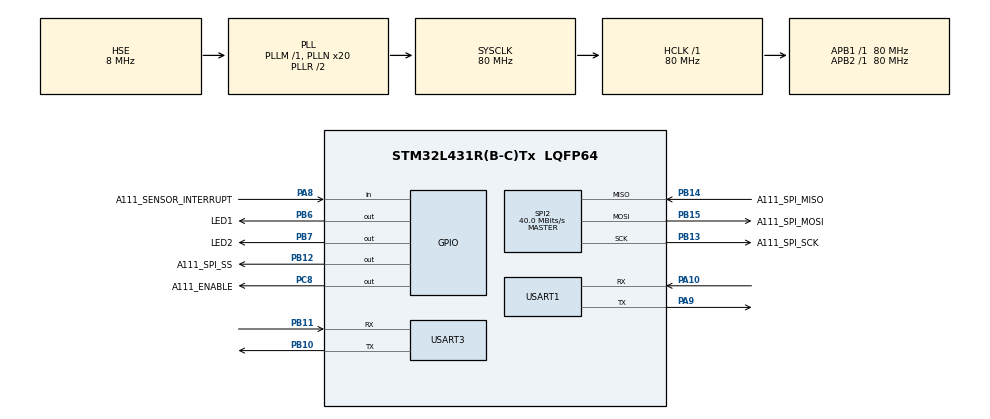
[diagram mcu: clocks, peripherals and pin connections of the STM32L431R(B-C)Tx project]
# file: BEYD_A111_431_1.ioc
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Mcu.Family=STM32L4
Mcu.Name=STM32L431R(B-C)Tx
Mcu.Package=LQFP64
NVIC.PriorityGroup=NVIC_PRIORITYGROUP_4
PA10.Mode=Asynchronous
PA10.Signal=USART1_RX
PA2.Signal=USART2_TX
PA3.Signal=USART2_RX
PA8.GPIO_Label=A111_SENSOR_INTERRUPT
PA8.Signal=GPIO_Input
PA9.Mode=Asynchronous
PA9.Signal=USART1_TX
PB10.Mode=Asynchronous
PB10.Signal=USART3_TX
PB11.Mode=Asynchronous
PB11.Signal=USART3_RX
PB12.GPIO_Label=A111_SPI_SS
PB12.Signal=GPIO_Output
PB13.GPIO_Label=A111_SPI_SCK
PB13.GPIO_Mode=GPIO_MODE_AF_PP
PB13.GPIO_PuPd=GPIO_NOPULL
PB13.GPIO_Speed=GPIO_SPEED_FREQ_VERY_HIGH
PB13.Mode=Full_Duplex_Master
PB13.Signal=SPI2_SCK
PB14.GPIO_Label=A111_SPI_MISO
PB14.GPIO_Mode=GPIO_MODE_AF_PP
PB14.GPIO_PuPd=GPIO_NOPULL
PB14.GPIO_Speed=GPIO_SPEED_FREQ_VERY_HIGH
PB14.Mode=Full_Duplex_Master
PB14.Signal=SPI2_MISO
PB15.GPIO_Label=A111_SPI_MOSI
PB15.GPIO_Mode=GPIO_MODE_AF_PP
PB15.GPIO_PuPd=GPIO_NOPULL
PB15.GPIO_Speed=GPIO_SPEED_FREQ_VERY_HIGH
PB15.Mode=Full_Duplex_Master
PB15.Signal=SPI2_MOSI
PB6.GPIO_Label=LED1
PB6.Signal=GPIO_Output
PB7.GPIO_Label=LED2
PB7.Signal=GPIO_Output
PC8.GPIO_Label=A111_ENABLE
PC8.Signal=GPIO_Output
PH0-OSC_IN\ (PH0).Mode=HSE-External-Oscillator
PH0-OSC_IN\ (PH0).Signal=RCC_OSC_IN
PH1-OSC_OUT\ (PH1).Mode=HSE-External-Oscillator
PH1-OSC_OUT\ (PH1).Signal=RCC_OSC_OUT
ProjectManager.HeapSize=0x200
ProjectManager.StackSize=0x400
ProjectManager.TargetToolchain=TrueSTUDIO
RCC.ADCFreq_Value=32000000
RCC.AHBFreq_Value=80000000
RCC.APB1Freq_Value=80000000
RCC.APB1TimFreq_Value=80000000
RCC.APB2Freq_Value=80000000
RCC.APB2TimFreq_Value=80000000
RCC.CortexFreq_Value=80000000
RCC.HCLKFreq_Value=80000000
RCC.HSE_VALUE=8000000
RCC.HSI48_VALUE=48000000
RCC.HSI_VALUE=16000000
RCC.LSE_VALUE=32768
RCC.MSI_VALUE=4000000
RCC.PLLN=20
RCC.PLLSourceVirtual=RCC_PLLSOURCE_HSE
RCC.SYSCLKFreq_VALUE=80000000
RCC.SYSCLKSource=RCC_SYSCLKSOURCE_PLLCLK
RCC.VCOOutputFreq_Value=160000000
SPI2.CalculateBaudRate=40.0 MBits/s
SPI2.Direction=SPI_DIRECTION_2LINES
SPI2.Mode=SPI_MODE_MASTER
SPI2.VirtualType=VM_MASTER
USART1.VirtualMode-Asynchronous=VM_ASYNC
USART3.VirtualMode-Asynchronous=VM_ASYNC
board=custom

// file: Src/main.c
/* USER CODE BEGIN Header */
/**
  ******************************************************************************
  * @file           : main.c
  * @brief          : Main program body
  ******************************************************************************
  ** This notice applies to any and all portions of this file
  * that are not between comment pairs USER CODE BEGIN and
  * USER CODE END. Other portions of this file, whether
  * inserted by the user or by software development tools
  * are owned by their respective copyright owners.
  *
  * COPYRIGHT(c) 2019 STMicroelectronics
  *
  * Redistribution and use in source and binary forms, with or without modification,
  * are permitted provided that the following conditions are met:
  *   1. Redistributions of source code must retain the above copyright notice,
  *      this list of conditions and the following disclaimer.
  *   2. Redistributions in binary form must reproduce the above copyright notice,
  *      this list of conditions and the following disclaimer in the documentation
  *      and/or other materials provided with the distribution.
  *   3. Neither the name of STMicroelectronics nor the names of its contributors
  *      may be used to endorse or promote products derived from this software
  *      without specific prior written permission.
  *
  * THIS SOFTWARE IS PROVIDED BY THE COPYRIGHT HOLDERS AND CONTRIBUTORS "AS IS"
  * AND ANY EXPRESS OR IMPLIED WARRANTIES, INCLUDING, BUT NOT LIMITED TO, THE
  * IMPLIED WARRANTIES OF MERCHANTABILITY AND FITNESS FOR A PARTICULAR PURPOSE ARE
  * DISCLAIMED. IN NO EVENT SHALL THE COPYRIGHT HOLDER OR CONTRIBUTORS BE LIABLE
  * FOR ANY DIRECT, INDIRECT, INCIDENTAL, SPECIAL, EXEMPLARY, OR CONSEQUENTIAL
  * DAMAGES (INCLUDING, BUT NOT LIMITED TO, PROCUREMENT OF SUBSTITUTE GOODS OR
  * SERVICES; LOSS OF USE, DATA, OR PROFITS; OR BUSINESS INTERRUPTION) HOWEVER
  * CAUSED AND ON ANY THEORY OF LIABILITY, WHETHER IN CONTRACT, STRICT LIABILITY,
  * OR TORT (INCLUDING NEGLIGENCE OR OTHERWISE) ARISING IN ANY WAY OUT OF THE USE
  * OF THIS SOFTWARE, EVEN IF ADVISED OF THE POSSIBILITY OF SUCH DAMAGE.
  *
  ******************************************************************************
  */
/* USER CODE END Header */

#include "main.h"
#include "stm32l4xx_hal.h"
#include "spi.h"
#include "usart.h"
#include "gpio.h"
#include "example_power_bin_once.h"
#include "distance_peak_fun.h"
#include "A111_test.h"
#include "acc_log.h"

void SystemClock_Config(void);

/* USER CODE BEGIN 2 */

extern uint8_t aRxBuffer[1];//HAL库USART接收Buffer

acc_log_level_enum_t log_temp;
int main(void)
{
  /* USER CODE BEGIN 1 */

  /* USER CODE END 1 */

  /* MCU Configuration--------------------------------------------------------*/

  /* Reset of all peripherals, Initializes the Flash interface and the Systick. */
  HAL_Init();

  /* USER CODE BEGIN Init */

  /* USER CODE END Init */

  /* Configure the system clock */
  SystemClock_Config();
  HAL_Delay(1000);//5s
  /* USER CODE BEGIN SysInit */

  /* USER CODE END SysInit */
  /* Initialize all configured peripherals */
  MX_GPIO_Init();
  MX_SPI2_Init();
  MX_USART1_UART_Init();
  MX_USART3_UART_Init();

  HAL_UART_Receive_IT(&huart1, (uint8_t *)&aRxBuffer, 1);
  /* USER CODE BEGIN 2 */
  /* USER CODE END 2 */

  //UART_send_data("booted\n");

  POWER_ON
  /* Infinite loop */
  /* USER CODE BEGIN WHILE */

  while (1)
  {
	//  acc_sparse();

//	  select_mode();
//	  acc_example_funtion();
//	  HAL_UART_RxCpltCallback(&huart1);
//	  select_mode();rn c
    //USER CODE END WHILE
//	  acc_example_detector_distance_peak_fixed_threshold();
//	  acc_dist_peak();
//	  acc_dist_funtion();
	  acc_example_power_bin_once();

//	  SoftReset();

	  LED1_ON
	  LED2_OFF
	  HAL_Delay(500);

	  LED1_OFF
	  LED2_ON
	  //HAL_Delay(600);
    }

  /* USER CODE END 3 */
}

void SystemClock_Config(void)
{
  RCC_OscInitTypeDef RCC_OscInitStruct = {0};
  RCC_ClkInitTypeDef RCC_ClkInitStruct = {0};
  RCC_PeriphCLKInitTypeDef PeriphClkInit = {0};

  /**Initializes the CPU, AHB and APB busses clocks
  */
  RCC_OscInitStruct.OscillatorType = RCC_OSCILLATORTYPE_HSE;
  RCC_OscInitStruct.HSEState = RCC_HSE_ON;
  RCC_OscInitStruct.PLL.PLLState = RCC_PLL_ON;
  RCC_OscInitStruct.PLL.PLLSource = RCC_PLLSOURCE_HSE;
  RCC_OscInitStruct.PLL.PLLM = 1;
  RCC_OscInitStruct.PLL.PLLN = 20;
  RCC_OscInitStruct.PLL.PLLP = RCC_PLLP_DIV7;
  RCC_OscInitStruct.PLL.PLLQ = RCC_PLLQ_DIV2;
  RCC_OscInitStruct.PLL.PLLR = RCC_PLLR_DIV2;
  if (HAL_RCC_OscConfig(&RCC_OscInitStruct) != HAL_OK)
  {
    Error_Handler();
  }
  /**Initializes the CPU, AHB and APB busses clocks
  */
  RCC_ClkInitStruct.ClockType = RCC_CLOCKTYPE_HCLK|RCC_CLOCKTYPE_SYSCLK
                              |RCC_CLOCKTYPE_PCLK1|RCC_CLOCKTYPE_PCLK2;
  RCC_ClkInitStruct.SYSCLKSource = RCC_SYSCLKSOURCE_PLLCLK;
  RCC_ClkInitStruct.AHBCLKDivider = RCC_SYSCLK_DIV1;
  RCC_ClkInitStruct.APB1CLKDivider = RCC_HCLK_DIV1;
  RCC_ClkInitStruct.APB2CLKDivider = RCC_HCLK_DIV1;

  if (HAL_RCC_ClockConfig(&RCC_ClkInitStruct, FLASH_LATENCY_4) != HAL_OK)
  {
    Error_Handler();
  }
  PeriphClkInit.PeriphClockSelection = RCC_PERIPHCLK_USART1|RCC_PERIPHCLK_USART3;
  PeriphClkInit.Usart1ClockSelection = RCC_USART1CLKSOURCE_PCLK2;
  PeriphClkInit.Usart3ClockSelection = RCC_USART3CLKSOURCE_PCLK1;
  if (HAL_RCCEx_PeriphCLKConfig(&PeriphClkInit) != HAL_OK)
  {
    Error_Handler();
  }
  /**Configure the main internal regulator output voltage
  */
  if (HAL_PWREx_ControlVoltageScaling(PWR_REGULATOR_VOLTAGE_SCALE1) != HAL_OK)
  {
    Error_Handler();
  }
}

void Error_Handler(void)
{
}

/************************ (C) COPYRIGHT STMicroelectronics *****END OF FILE****/
